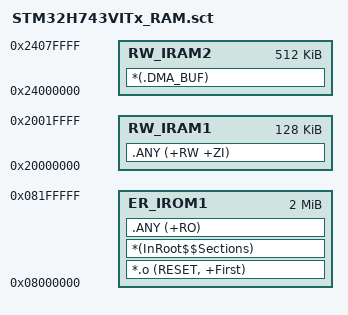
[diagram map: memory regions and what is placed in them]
; *************************************************************
; *** STM32H743VI scatter file: 代码在 Flash，数据在 DTCM，DMA 缓冲在 AXI SRAM ***
; *** DMA1/DMA2 无法访问 DTCM(0x20000000)，必须将 DMA 缓冲放在 AXI SRAM(0x24000000) ***
; *************************************************************

LR_IROM1 0x08000000 0x00200000 {
  ER_IROM1 0x08000000 0x00200000 {
    *.o (RESET, +First)
    *(InRoot$$Sections)
    .ANY (+RO)
  }
  ; DTCM: 128KB，用于 stack/heap/默认数据（DMA 不可访问）
  RW_IRAM1 0x20000000 0x00020000 {
    .ANY (+RW +ZI)
  }
  ; AXI SRAM: 512KB，DMA 可访问，仅放 UART DMA TX 缓冲
  RW_IRAM2 0x24000000 0x00080000 {
    *(.DMA_BUF)
  }
}
